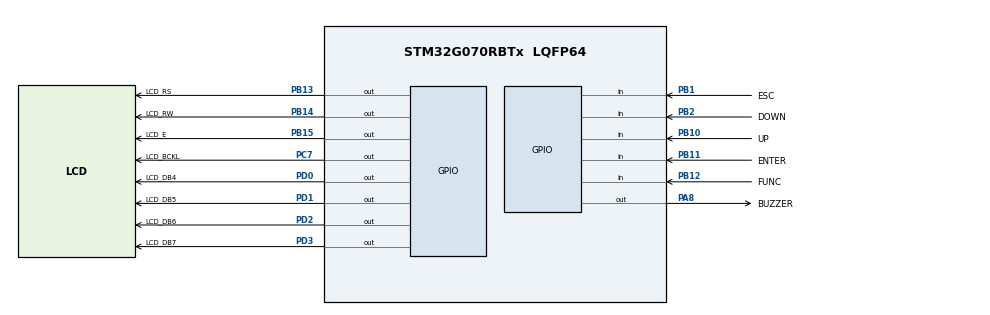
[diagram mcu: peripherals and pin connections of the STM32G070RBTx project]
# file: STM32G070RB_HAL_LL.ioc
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Mcu.Family=STM32G0
Mcu.Name=STM32G070RBTx
Mcu.Package=LQFP64
PA13.Mode=Serial_Wire
PA13.Signal=SYS_SWDIO
PA14-BOOT0.Mode=Serial_Wire
PA14-BOOT0.Signal=SYS_SWCLK
PA8.GPIO_Label=BUZZER
PA8.Signal=GPIO_Output
PB1.GPIO_Label=ESC
PB1.Signal=GPIO_Input
PB10.GPIO_Label=UP
PB10.Signal=GPIO_Input
PB11.GPIO_Label=ENTER
PB11.Signal=GPIO_Input
PB12.GPIO_Label=FUNC
PB12.Signal=GPIO_Input
PB13.GPIO_Label=LCD_RS
PB13.Signal=GPIO_Output
PB14.GPIO_Label=LCD_RW
PB14.Signal=GPIO_Output
PB15.GPIO_Label=LCD_E
PB15.Signal=GPIO_Output
PB2.GPIO_Label=DOWN
PB2.Signal=GPIO_Input
PC7.GPIO_Label=LCD_BCKL
PC7.Signal=GPIO_Output
PD0.GPIO_Label=LCD_DB4
PD0.Signal=GPIO_Output
PD1.GPIO_Label=LCD_DB5
PD1.Signal=GPIO_Output
PD2.GPIO_Label=LCD_DB6
PD2.Signal=GPIO_Output
PD3.GPIO_Label=LCD_DB7
PD3.Signal=GPIO_Output
ProjectManager.HeapSize=0x200
ProjectManager.StackSize=0x400
ProjectManager.TargetToolchain=STM32CubeIDE
RCC.ADCFreq_Value=64000000
RCC.AHBFreq_Value=64000000
RCC.CortexFreq_Value=64000000
RCC.EXTERNAL_CLOCK_VALUE=48000
RCC.HCLKFreq_Value=64000000
RCC.HSE_VALUE=8000000
RCC.HSI_VALUE=16000000
RCC.RTCClockSelection=RCC_RTCCLKSOURCE_LSE
RCC.SYSCLKFreq_VALUE=64000000
RCC.SYSCLKSource=RCC_SYSCLKSOURCE_PLLCLK
RCC.VCOOutputFreq_Value=128000000
board=custom

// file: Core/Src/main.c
/* USER CODE BEGIN Header */
/**
  ******************************************************************************
  * @file           : main.c
  * @brief          : Main program body
  ******************************************************************************
  * @attention
  *
  * Copyright (c) 2025 STMicroelectronics.
  * All rights reserved.
  *
  * This software is licensed under terms that can be found in the LICENSE file
  * in the root directory of this software component.
  * If no LICENSE file comes with this software, it is provided AS-IS.
  *
  ******************************************************************************
  */
/* USER CODE END Header */
#include "main.h"
#include "main_app.h"

void SystemClock_Config(void);

int main(void)
{

  /* MCU Configuration--------------------------------------------------------*/

  /* Reset of all peripherals, Initializes the Flash interface and the Systick. */
  LL_APB2_GRP1_EnableClock(LL_APB2_GRP1_PERIPH_SYSCFG);
  LL_APB1_GRP1_EnableClock(LL_APB1_GRP1_PERIPH_PWR);

  /* SysTick_IRQn interrupt configuration */
  NVIC_SetPriority(SysTick_IRQn, 3);

  /* Configure the system clock */
  SystemClock_Config();

  /* Initialize all configured peripherals */
  /* USER CODE BEGIN 2 */
  LL_SYSTICK_EnableIT();
  /* USER CODE END 2 */

  /* Infinite loop */
  /* USER CODE BEGIN WHILE */
  while (1)
  {
    main_app();
    /* USER CODE END WHILE */

  }
}

void SystemClock_Config(void)
{
  LL_FLASH_SetLatency(LL_FLASH_LATENCY_2);
  while(LL_FLASH_GetLatency() != LL_FLASH_LATENCY_2)
  {
  }

  /* HSI configuration and activation */
  LL_RCC_HSI_Enable();
  while(LL_RCC_HSI_IsReady() != 1)
  {
  }

  /* Main PLL configuration and activation */
  LL_RCC_PLL_ConfigDomain_SYS(LL_RCC_PLLSOURCE_HSI, LL_RCC_PLLM_DIV_1, 8, LL_RCC_PLLR_DIV_2);
  LL_RCC_PLL_Enable();
  LL_RCC_PLL_EnableDomain_SYS();
  while(LL_RCC_PLL_IsReady() != 1)
  {
  }

  /* Set AHB prescaler*/
  LL_RCC_SetAHBPrescaler(LL_RCC_SYSCLK_DIV_1);

  /* Sysclk activation on the main PLL */
  LL_RCC_SetSysClkSource(LL_RCC_SYS_CLKSOURCE_PLL);
  while(LL_RCC_GetSysClkSource() != LL_RCC_SYS_CLKSOURCE_STATUS_PLL)
  {
  }

  /* Set APB1 prescaler*/
  LL_RCC_SetAPB1Prescaler(LL_RCC_APB1_DIV_1);
  LL_Init1msTick(64000000);
  /* Update CMSIS variable (which can be updated also through SystemCoreClockUpdate function) */
  LL_SetSystemCoreClock(64000000);
}

void MX_GPIO_Init(void)
{
  LL_GPIO_InitTypeDef GPIO_InitStruct = {0};

  /* GPIO Ports Clock Enable */
  LL_IOP_GRP1_EnableClock(LL_IOP_GRP1_PERIPH_GPIOB);
  LL_IOP_GRP1_EnableClock(LL_IOP_GRP1_PERIPH_GPIOA);
  LL_IOP_GRP1_EnableClock(LL_IOP_GRP1_PERIPH_GPIOC);
  LL_IOP_GRP1_EnableClock(LL_IOP_GRP1_PERIPH_GPIOD);

  /**/
  LL_GPIO_ResetOutputPin(LCD_RS_GPIO_Port, LCD_RS_Pin);

  /**/
  LL_GPIO_ResetOutputPin(LCD_RW_GPIO_Port, LCD_RW_Pin);

  /**/
  LL_GPIO_ResetOutputPin(LCD_E_GPIO_Port, LCD_E_Pin);

  /**/
  LL_GPIO_ResetOutputPin(BUZZER_GPIO_Port, BUZZER_Pin);

  /**/
  LL_GPIO_ResetOutputPin(LCD_BCKL_GPIO_Port, LCD_BCKL_Pin);

  /**/
  LL_GPIO_ResetOutputPin(LCD_DB4_GPIO_Port, LCD_DB4_Pin);

  /**/
  LL_GPIO_ResetOutputPin(LCD_DB5_GPIO_Port, LCD_DB5_Pin);

  /**/
  LL_GPIO_ResetOutputPin(LCD_DB6_GPIO_Port, LCD_DB6_Pin);

  /**/
  LL_GPIO_ResetOutputPin(LCD_DB7_GPIO_Port, LCD_DB7_Pin);

  /**/
  GPIO_InitStruct.Pin = ESC_Pin;
  GPIO_InitStruct.Mode = LL_GPIO_MODE_INPUT;
  GPIO_InitStruct.Pull = LL_GPIO_PULL_NO;
  LL_GPIO_Init(ESC_GPIO_Port, &GPIO_InitStruct);

  /**/
  GPIO_InitStruct.Pin = DOWN_Pin;
  GPIO_InitStruct.Mode = LL_GPIO_MODE_INPUT;
  GPIO_InitStruct.Pull = LL_GPIO_PULL_NO;
  LL_GPIO_Init(DOWN_GPIO_Port, &GPIO_InitStruct);

  /**/
  GPIO_InitStruct.Pin = UP_Pin;
  GPIO_InitStruct.Mode = LL_GPIO_MODE_INPUT;
  GPIO_InitStruct.Pull = LL_GPIO_PULL_NO;
  LL_GPIO_Init(UP_GPIO_Port, &GPIO_InitStruct);

  /**/
  GPIO_InitStruct.Pin = ENTER_Pin;
  GPIO_InitStruct.Mode = LL_GPIO_MODE_INPUT;
  GPIO_InitStruct.Pull = LL_GPIO_PULL_NO;
  LL_GPIO_Init(ENTER_GPIO_Port, &GPIO_InitStruct);

  /**/
  GPIO_InitStruct.Pin = FUNC_Pin;
  GPIO_InitStruct.Mode = LL_GPIO_MODE_INPUT;
  GPIO_InitStruct.Pull = LL_GPIO_PULL_NO;
  LL_GPIO_Init(FUNC_GPIO_Port, &GPIO_InitStruct);

  /**/
  GPIO_InitStruct.Pin = LCD_RS_Pin;
  GPIO_InitStruct.Mode = LL_GPIO_MODE_OUTPUT;
  GPIO_InitStruct.Speed = LL_GPIO_SPEED_FREQ_LOW;
  GPIO_InitStruct.OutputType = LL_GPIO_OUTPUT_PUSHPULL;
  GPIO_InitStruct.Pull = LL_GPIO_PULL_NO;
  LL_GPIO_Init(LCD_RS_GPIO_Port, &GPIO_InitStruct);

  /**/
  GPIO_InitStruct.Pin = LCD_RW_Pin;
  GPIO_InitStruct.Mode = LL_GPIO_MODE_OUTPUT;
  GPIO_InitStruct.Speed = LL_GPIO_SPEED_FREQ_LOW;
  GPIO_InitStruct.OutputType = LL_GPIO_OUTPUT_PUSHPULL;
  GPIO_InitStruct.Pull = LL_GPIO_PULL_NO;
  LL_GPIO_Init(LCD_RW_GPIO_Port, &GPIO_InitStruct);

  /**/
  GPIO_InitStruct.Pin = LCD_E_Pin;
  GPIO_InitStruct.Mode = LL_GPIO_MODE_OUTPUT;
  GPIO_InitStruct.Speed = LL_GPIO_SPEED_FREQ_LOW;
  GPIO_InitStruct.OutputType = LL_GPIO_OUTPUT_PUSHPULL;
  GPIO_InitStruct.Pull = LL_GPIO_PULL_NO;
  LL_GPIO_Init(LCD_E_GPIO_Port, &GPIO_InitStruct);

  /**/
  GPIO_InitStruct.Pin = BUZZER_Pin;
  GPIO_InitStruct.Mode = LL_GPIO_MODE_OUTPUT;
  GPIO_InitStruct.Speed = LL_GPIO_SPEED_FREQ_LOW;
  GPIO_InitStruct.OutputType = LL_GPIO_OUTPUT_PUSHPULL;
  GPIO_InitStruct.Pull = LL_GPIO_PULL_NO;
  LL_GPIO_Init(BUZZER_GPIO_Port, &GPIO_InitStruct);

  /**/
  GPIO_InitStruct.Pin = LCD_BCKL_Pin;
  GPIO_InitStruct.Mode = LL_GPIO_MODE_OUTPUT;
  GPIO_InitStruct.Speed = LL_GPIO_SPEED_FREQ_LOW;
  GPIO_InitStruct.OutputType = LL_GPIO_OUTPUT_PUSHPULL;
  GPIO_InitStruct.Pull = LL_GPIO_PULL_NO;
  LL_GPIO_Init(LCD_BCKL_GPIO_Port, &GPIO_InitStruct);

  /**/
  GPIO_InitStruct.Pin = LCD_DB4_Pin;
  GPIO_InitStruct.Mode = LL_GPIO_MODE_OUTPUT;
  GPIO_InitStruct.Speed = LL_GPIO_SPEED_FREQ_LOW;
  GPIO_InitStruct.OutputType = LL_GPIO_OUTPUT_PUSHPULL;
  GPIO_InitStruct.Pull = LL_GPIO_PULL_NO;
  LL_GPIO_Init(LCD_DB4_GPIO_Port, &GPIO_InitStruct);

  /**/
  GPIO_InitStruct.Pin = LCD_DB5_Pin;
  GPIO_InitStruct.Mode = LL_GPIO_MODE_OUTPUT;
  GPIO_InitStruct.Speed = LL_GPIO_SPEED_FREQ_LOW;
  GPIO_InitStruct.OutputType = LL_GPIO_OUTPUT_PUSHPULL;
  GPIO_InitStruct.Pull = LL_GPIO_PULL_NO;
  LL_GPIO_Init(LCD_DB5_GPIO_Port, &GPIO_InitStruct);

  /**/
  GPIO_InitStruct.Pin = LCD_DB6_Pin;
  GPIO_InitStruct.Mode = LL_GPIO_MODE_OUTPUT;
  GPIO_InitStruct.Speed = LL_GPIO_SPEED_FREQ_LOW;
  GPIO_InitStruct.OutputType = LL_GPIO_OUTPUT_PUSHPULL;
  GPIO_InitStruct.Pull = LL_GPIO_PULL_NO;
  LL_GPIO_Init(LCD_DB6_GPIO_Port, &GPIO_InitStruct);

  /**/
  GPIO_InitStruct.Pin = LCD_DB7_Pin;
  GPIO_InitStruct.Mode = LL_GPIO_MODE_OUTPUT;
  GPIO_InitStruct.Speed = LL_GPIO_SPEED_FREQ_LOW;
  GPIO_InitStruct.OutputType = LL_GPIO_OUTPUT_PUSHPULL;
  GPIO_InitStruct.Pull = LL_GPIO_PULL_NO;
  LL_GPIO_Init(LCD_DB7_GPIO_Port, &GPIO_InitStruct);

}

void Error_Handler(void)
{
  __disable_irq();
  while (1)
  {
  }
}
